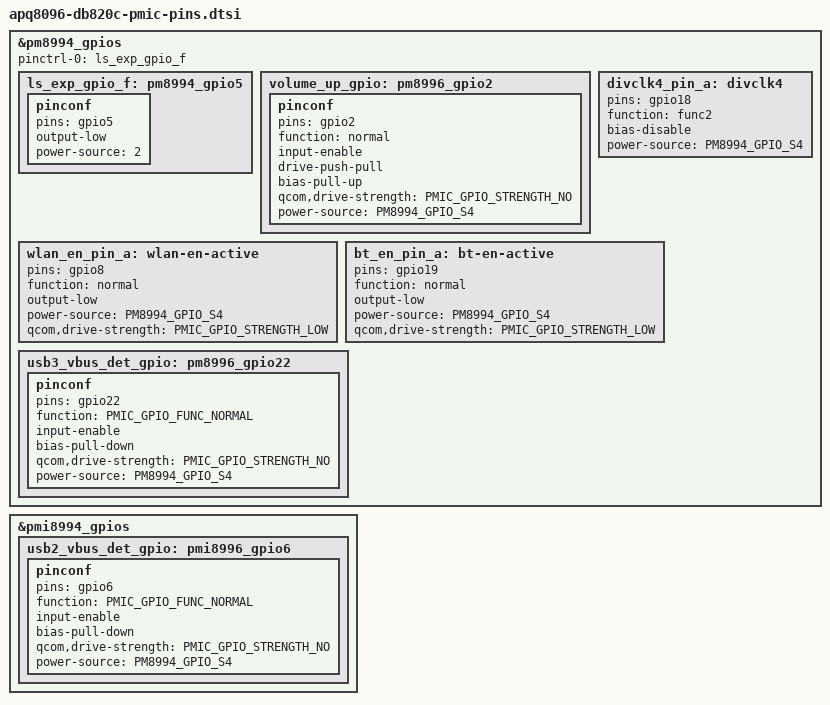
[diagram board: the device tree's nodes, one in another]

#include <dt-bindings/pinctrl/qcom,pmic-gpio.h>
&pm8994_gpios {

	pinctrl-names = "default";
	pinctrl-0 = <&ls_exp_gpio_f>;

	ls_exp_gpio_f: pm8994_gpio5 {
		pinconf {
			pins = "gpio5";
			output-low;
			power-source = <2>; // PM8994_GPIO_S4, 1.8V
		};
	};

	volume_up_gpio: pm8996_gpio2 {
		pinconf {
			pins = "gpio2";
			function = "normal";
			input-enable;
			drive-push-pull;
			bias-pull-up;
			qcom,drive-strength = <PMIC_GPIO_STRENGTH_NO>;
			power-source = <PM8994_GPIO_S4>; // 1.8V
		};
	};

	wlan_en_pin_a: wlan-en-active {
		pins = "gpio8";
		function = "normal";

		output-low;
		power-source = <PM8994_GPIO_S4>;
		qcom,drive-strength = <PMIC_GPIO_STRENGTH_LOW>;
	};

	divclk4_pin_a: divclk4 {
		pins = "gpio18";
		function = "func2";

		bias-disable;	
		power-source = <PM8994_GPIO_S4>;
	};

	bt_en_pin_a: bt-en-active {
		pins = "gpio19";
		function = "normal";

		output-low;
		power-source = <PM8994_GPIO_S4>;
		qcom,drive-strength = <PMIC_GPIO_STRENGTH_LOW>;
	};

	usb3_vbus_det_gpio: pm8996_gpio22 {
		pinconf {
			pins = "gpio22";
			function = PMIC_GPIO_FUNC_NORMAL;
			input-enable;
			bias-pull-down;
			qcom,drive-strength = <PMIC_GPIO_STRENGTH_NO>;
			power-source = <PM8994_GPIO_S4>; // 1.8V
		};
	};
};

&pmi8994_gpios {
	usb2_vbus_det_gpio: pmi8996_gpio6 {
		pinconf {
			pins = "gpio6";
			function = PMIC_GPIO_FUNC_NORMAL;
			input-enable;
			bias-pull-down;
			qcom,drive-strength = <PMIC_GPIO_STRENGTH_NO>;
			power-source = <PM8994_GPIO_S4>; // 1.8V
		};
	};
};
